# STM32N645xx register map
File version: 1.0
Registers are 32-bit, read-write, reset 0x0 unless marked. A register's access mark holds for its fields unless they carry their own. Offsets are from the block's base; [hi:lo] are bit positions; {n}, {i} and the like mark numbered series; 'fields as' and 'values as' point back to an identical list.

## ETH1 — Ethernet MAC
Base 0x48036000
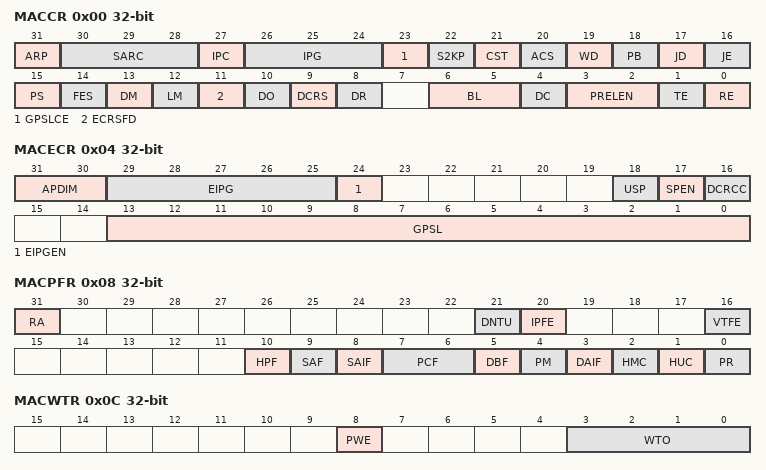
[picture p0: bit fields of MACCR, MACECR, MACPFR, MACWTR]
0x00 MACCR — Operating mode configuration register
  [31] ARP, [30:28] SARC, [27] IPC, [26:24] IPG, [23] GPSLCE, [22] S2KP, [21] CST, [20] ACS, [19] WD, [18] PB, [17] JD, [16] JE, [15] PS, [14] FES, [13] DM, [12] LM, [11] ECRSFD, [10] DO, [9] DCRS, [8] DR, [6:5] BL, [4] DC, [3:2] PRELEN, [1] TE, [0] RE
0x04 MACECR — Extended operating mode configuration register
  [31:30] APDIM, [29:25] EIPG, [24] EIPGEN, [18] USP, [17] SPEN, [16] DCRCC, [13:0] GPSL
0x08 MACPFR — Packet filtering control register
  [31] RA, [21] DNTU, [20] IPFE, [16] VTFE, [10] HPF, [9] SAF, [8] SAIF, [7:6] PCF, [5] DBF, [4] PM, [3] DAIF, [2] HMC, [1] HUC, [0] PR
0x0C MACWTR — Watchdog timeout register
  [8] PWE, [3:0] WTO
0x10 MACHT0R — Hash Table 0 register
0x14 MACHT1R — Hash Table 1 register
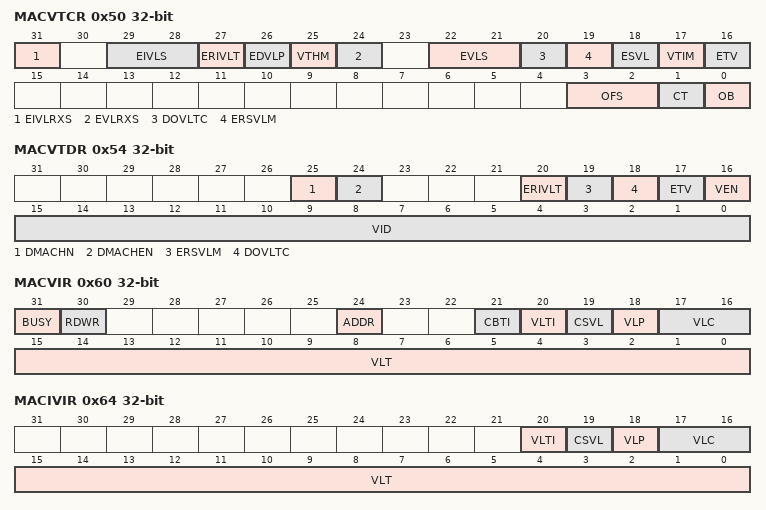
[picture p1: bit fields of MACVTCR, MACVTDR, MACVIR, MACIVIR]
0x50 MACVTCR — VLAN tag Control register
  [31] EIVLRXS, [29:28] EIVLS, [27] ERIVLT, [26] EDVLP, [25] VTHM, [24] EVLRXS, [22:21] EVLS, [20] DOVLTC, [19] ERSVLM, [18] ESVL, [17] VTIM, [16] ETV, [3:2] OFS, [1] CT, [0] OB
0x54 MACVTDR — VLAN tag data register
  [25] DMACHN, [24] DMACHEN, [20] ERIVLT, [19] ERSVLM, [18] DOVLTC, [17] ETV, [16] VEN, [15:0] VID
0x58 MACVHTR — VLAN Hash table register
  [15:0] VLHT
0x60 MACVIR — VLAN inclusion register
  [31] BUSY, [30] RDWR, [24] ADDR, [21] CBTI, [20] VLTI, [19] CSVL, [18] VLP, [17:16] VLC, [15:0] VLT
0x64 MACIVIR — Inner VLAN inclusion register
  [20] VLTI, [19] CSVL, [18] VLP, [17:16] VLC, [15:0] VLT
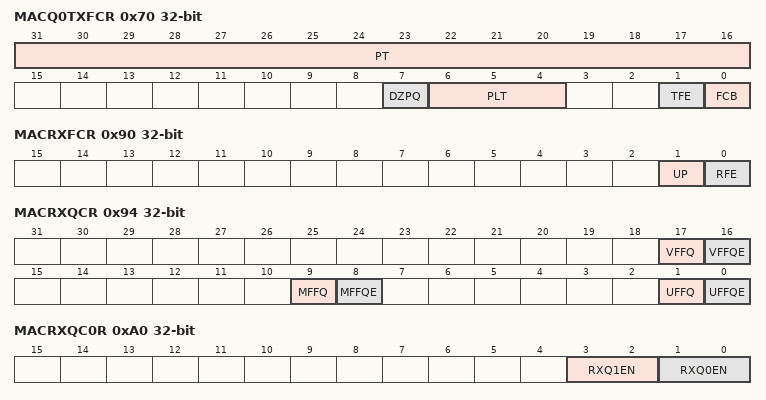
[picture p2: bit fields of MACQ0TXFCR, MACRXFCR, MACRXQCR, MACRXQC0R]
0x70 MACQ0TXFCR — Tx Queue 0 flow control register
  [31:16] PT, [7] DZPQ, [6:4] PLT, [1] TFE, [0] FCB
0x90 MACRXFCR — Rx flow control register
  [1] UP, [0] RFE
0x94 MACRXQCR — Rx Queue control register
  [17] VFFQ, [16] VFFQE, [9] MFFQ, [8] MFFQE, [1] UFFQ, [0] UFFQE
0xA0 MACRXQC0R — Rx queue control 0 register
  [3:2] RXQ1EN, [1:0] RXQ0EN
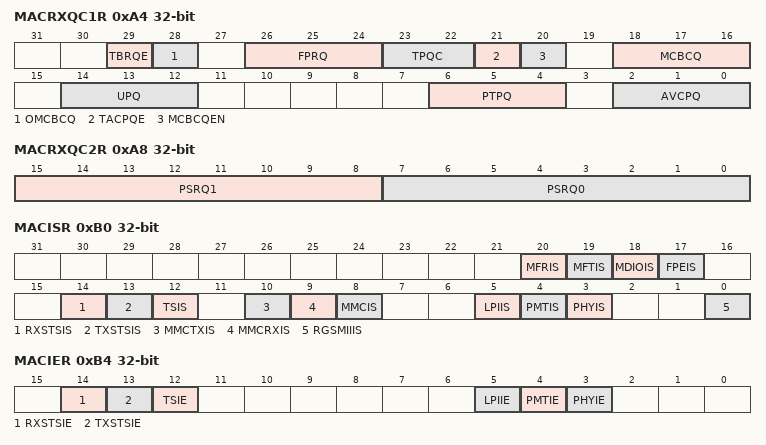
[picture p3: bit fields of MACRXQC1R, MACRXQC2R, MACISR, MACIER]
0xA4 MACRXQC1R — Rx queue control 1 register
  [29] TBRQE, [28] OMCBCQ, [26:24] FPRQ, [23:22] TPQC, [21] TACPQE, [20] MCBCQEN, [18:16] MCBCQ, [14:12] UPQ, [6:4] PTPQ, [2:0] AVCPQ
0xA8 MACRXQC2R — Rx queue control 2 register
  [15:8] PSRQ1, [7:0] PSRQ0
0xB0 MACISR — Interrupt status register
  [20] MFRIS, [19] MFTIS, [18] MDIOIS, [17] FPEIS, [14] RXSTSIS, [13] TXSTSIS, [12] TSIS, [10] MMCTXIS, [9] MMCRXIS, [8] MMCIS, [5] LPIIS, [4] PMTIS, [3] PHYIS, [0] RGSMIIIS
0xB4 MACIER — Interrupt enable register
  [14] RXSTSIE, [13] TXSTSIE, [12] TSIE, [5] LPIIE, [4] PMTIE, [3] PHYIE
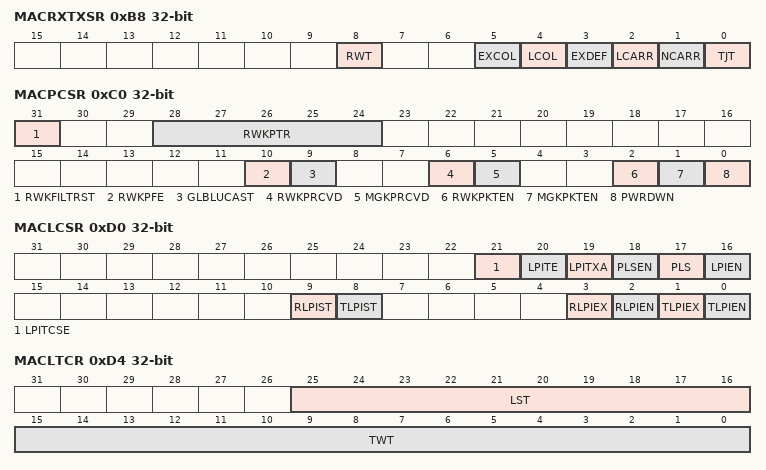
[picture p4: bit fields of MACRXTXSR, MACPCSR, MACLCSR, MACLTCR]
0xB8 MACRXTXSR — Rx Tx status register
  [8] RWT, [5] EXCOL, [4] LCOL, [3] EXDEF, [2] LCARR, [1] NCARR, [0] TJT
0xC0 MACPCSR — PMT control status register
  [31] RWKFILTRST, [28:24] RWKPTR, [10] RWKPFE, [9] GLBLUCAST, [6] RWKPRCVD, [5] MGKPRCVD, [2] RWKPKTEN, [1] MGKPKTEN, [0] PWRDWN
0xC4 MACRWKPFR — Remote wakeup packet filter register
0xD0 MACLCSR — LPI control and status register
  [21] LPITCSE, [20] LPITE, [19] LPITXA, [18] PLSEN, [17] PLS, [16] LPIEN, [9] RLPIST, [8] TLPIST, [3] RLPIEX, [2] RLPIEN, [1] TLPIEX, [0] TLPIEN
0xD4 MACLTCR — LPI timers control register
  [25:16] LST, [15:0] TWT
0xD8 MACLETR — LPI entry timer register
  [19:0] LPIET
0xDC MAC1USTCR — One-microsecond-tick counter register
  [11:0] TIC1USCNTR
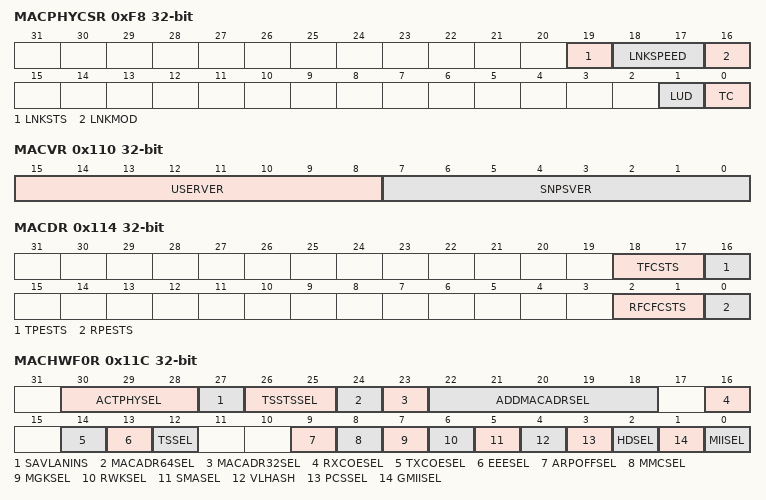
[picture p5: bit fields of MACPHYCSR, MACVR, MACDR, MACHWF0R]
0xF8 MACPHYCSR — PHYIF control status register
  [19] LNKSTS, [18:17] LNKSPEED, [16] LNKMOD, [1] LUD, [0] TC
0x110 MACVR — Version register
  [15:8] USERVER, [7:0] SNPSVER
0x114 MACDR — Debug register
  [18:17] TFCSTS, [16] TPESTS, [2:1] RFCFCSTS, [0] RPESTS
0x11C MACHWF0R — HW feature 0 register
  [30:28] ACTPHYSEL, [27] SAVLANINS, [26:25] TSSTSSEL, [24] MACADR64SEL, [23] MACADR32SEL, [22:18] ADDMACADRSEL, [16] RXCOESEL, [14] TXCOESEL, [13] EEESEL, [12] TSSEL, [9] ARPOFFSEL, [8] MMCSEL, [7] MGKSEL, [6] RWKSEL, [5] SMASEL, [4] VLHASH, [3] PCSSEL, [2] HDSEL, [1] GMIISEL, [0] MIISEL
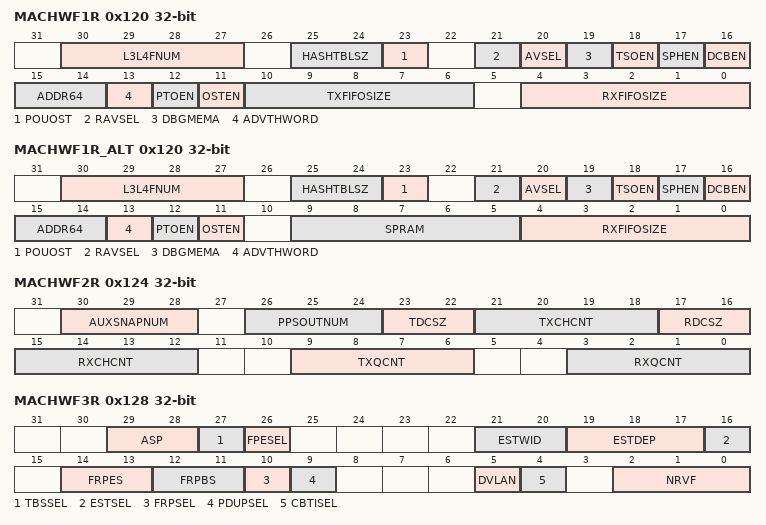
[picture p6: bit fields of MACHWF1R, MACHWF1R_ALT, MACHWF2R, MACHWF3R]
0x120 MACHWF1R — HW feature 1 register
  [30:27] L3L4FNUM, [25:24] HASHTBLSZ, [23] POUOST, [21] RAVSEL, [20] AVSEL, [19] DBGMEMA, [18] TSOEN, [17] SPHEN, [16] DCBEN, [15:14] ADDR64, [13] ADVTHWORD, [12] PTOEN, [11] OSTEN, [10:6] TXFIFOSIZE, [4:0] RXFIFOSIZE
0x120 MACHWF1R_ALT (alternate view of MACHWF1R) — HW feature 1 register
  [30:27] L3L4FNUM, [25:24] HASHTBLSZ, [23] POUOST, [21] RAVSEL, [20] AVSEL, [19] DBGMEMA, [18] TSOEN, [17] SPHEN, [16] DCBEN, [15:14] ADDR64, [13] ADVTHWORD, [12] PTOEN, [11] OSTEN, [9:5] SPRAM, [4:0] RXFIFOSIZE
0x124 MACHWF2R — HW feature 2 register
  [30:28] AUXSNAPNUM, [26:24] PPSOUTNUM, [23:22] TDCSZ, [21:18] TXCHCNT, [17:16] RDCSZ, [15:12] RXCHCNT, [9:6] TXQCNT, [3:0] RXQCNT
0x128 MACHWF3R — HW feature 3 register
  [29:28] ASP, [27] TBSSEL, [26] FPESEL, [21:20] ESTWID, [19:17] ESTDEP, [16] ESTSEL, [14:13] FRPES, [12:11] FRPBS, [10] FRPSEL, [9] PDUPSEL, [5] DVLAN, [4] CBTISEL, [2:0] NRVF
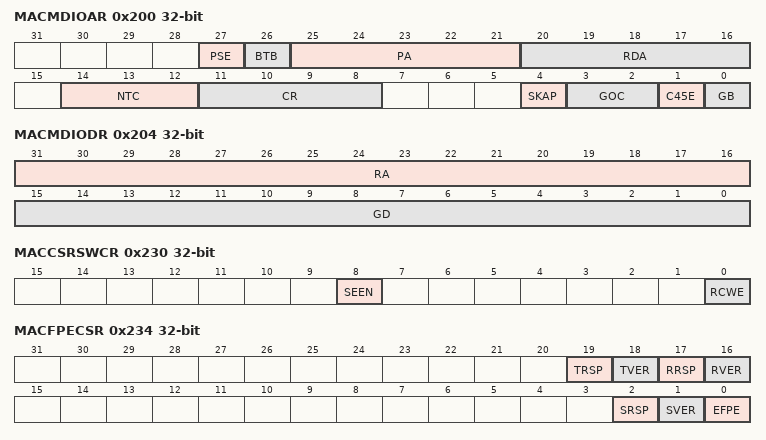
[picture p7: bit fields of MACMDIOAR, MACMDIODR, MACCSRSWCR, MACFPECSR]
0x200 MACMDIOAR — MDIO address register
  [27] PSE, [26] BTB, [25:21] PA, [20:16] RDA, [14:12] NTC, [11:8] CR, [4] SKAP, [3:2] GOC, [1] C45E, [0] GB
0x204 MACMDIODR — MDIO data register
  [31:16] RA, [15:0] GD
0x210 MACARPAR — ARP address register
  [31:0] ARPPA
0x230 MACCSRSWCR — CSR software control register
  [8] SEEN, [0] RCWE
0x234 MACFPECSR — FPE control and status register
  [19] TRSP, [18] TVER, [17] RRSP, [16] RVER, [2] SRSP, [1] SVER, [0] EFPE
0x240 MACPRSTIMR — MAC presentation time register
  [31:0] MPTN
0x244 MACPRSTIMUR — MAC presentation time update register
  [31:0] MPTU
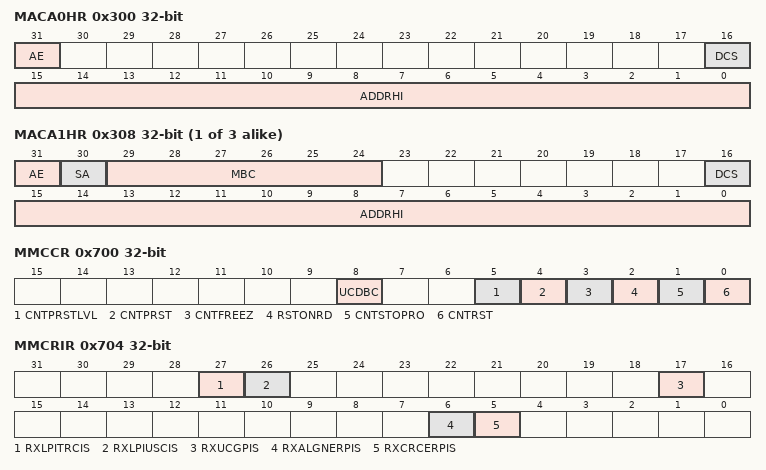
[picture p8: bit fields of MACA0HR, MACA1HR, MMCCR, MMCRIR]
0x300 MACA0HR — MAC Address 0 high register
  [31] AE, [16] DCS, [15:0] ADDRHI
{0x304+8i} MACA{i}LR (i=0..3) — MAC Address {i} low register
  [31:0] ADDRLO
{0x300+8i} MACA{i}HR (i=1..3) — MAC Address {i} high register
  [31] AE, [30] SA, [29:24] MBC, [16] DCS, [15:0] ADDRHI
0x700 MMCCR — MMC control register
  [8] UCDBC, [5] CNTPRSTLVL, [4] CNTPRST, [3] CNTFREEZ, [2] RSTONRD, [1] CNTSTOPRO, [0] CNTRST
0x704 MMCRIR — MMC Rx interrupt register
  [27] RXLPITRCIS, [26] RXLPIUSCIS, [17] RXUCGPIS, [6] RXALGNERPIS, [5] RXCRCERPIS
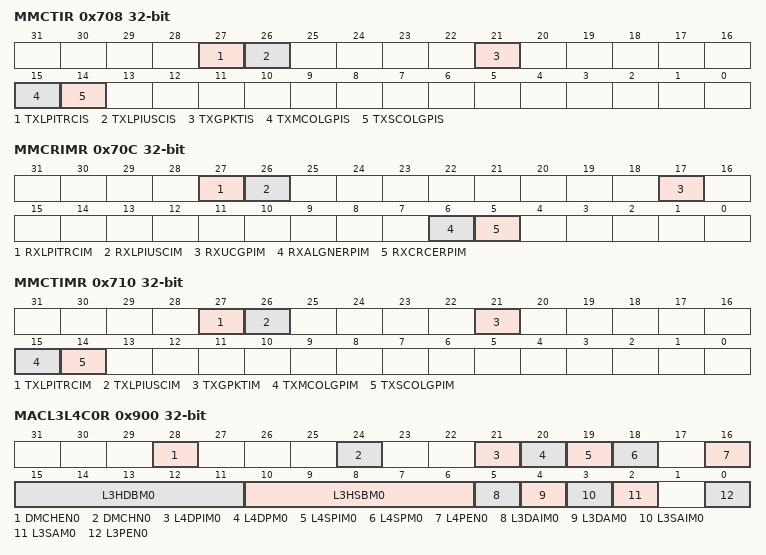
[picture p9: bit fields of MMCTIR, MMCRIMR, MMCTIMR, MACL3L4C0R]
0x708 MMCTIR — MMC Tx interrupt register
  [27] TXLPITRCIS, [26] TXLPIUSCIS, [21] TXGPKTIS, [15] TXMCOLGPIS, [14] TXSCOLGPIS
0x70C MMCRIMR — MMC Rx interrupt mask register
  [27] RXLPITRCIM, [26] RXLPIUSCIM, [17] RXUCGPIM, [6] RXALGNERPIM, [5] RXCRCERPIM
0x710 MMCTIMR — MMC Tx interrupt mask register
  [27] TXLPITRCIM, [26] TXLPIUSCIM, [21] TXGPKTIM, [15] TXMCOLGPIM, [14] TXSCOLGPIM
0x74C MMCTSCGPR — Tx single collision good packets register
0x750 MMCTMCGPR — Tx multiple collision good packets register
0x768 MMCTPCGR — Tx packet count good register
0x794 MMCRCRCEPR — Rx CRC error packets register
0x798 MMCRAEPR — Rx alignment error packets register
0x7C4 MMCRUPGR — Rx unicast packets good register
0x7EC MMCTLPIMSTR — Tx LPI microsecond timer register
0x7F0 MMCTLPITCR — Tx LPI transition counter register
0x7F4 MMCRLPIMSTR — Rx LPI microsecond counter register
0x7F8 MMCRLPITCR — Rx LPI transition counter register
0x8A0 MMCFPETISR — MMC FPE Tx interrupt status register
0x8A4 MMCFPETIMR — MMC FPE Tx interrupt mask register
0x8A8 MMCFPETFCR — MMC FPE Tx fragment counter register, -
0x8AC MMCTHRCR — MMC Tx hold request counter register
0x8C0 MMCFPERISR — MMC FPE Rx interrupt status register
0x8C4 MMCFPERIMR — MMC FPE Rx interrupt mask register
0x8C8 MMCRPAER — MMC Rx packet assembly error register
0x8CC MMCRPSMDER — MMC Rx packet SMD error register
0x8D0 MMCRPAOKR — MMC Rx packet assembly OK register
0x8D4 MMCFPERFCR — MMC Rx FPE fragments counter register
0x900 MACL3L4C0R — L3 and L4 control 0 register
  [28] DMCHEN0, [24] DMCHN0, [21] L4DPIM0, [20] L4DPM0, [19] L4SPIM0, [18] L4SPM0, [16] L4PEN0, [15:11] L3HDBM0, [10:6] L3HSBM0, [5] L3DAIM0, [4] L3DAM0, [3] L3SAIM0, [2] L3SAM0, [0] L3PEN0
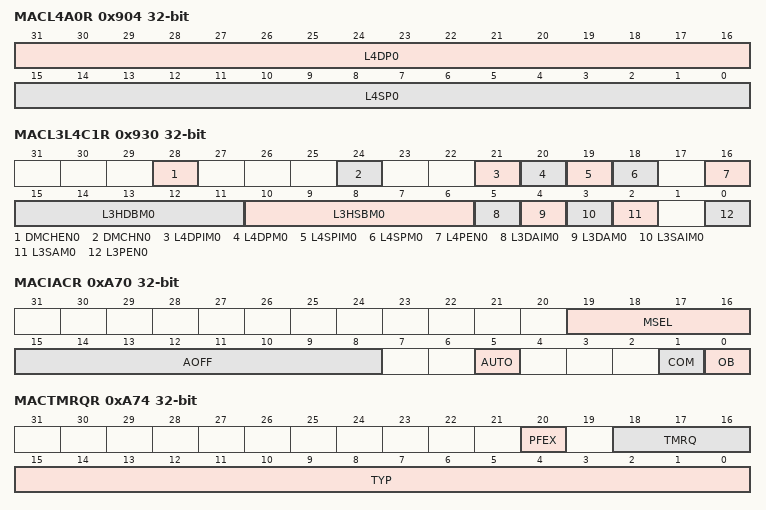
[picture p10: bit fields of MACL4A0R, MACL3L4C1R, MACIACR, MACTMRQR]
0x904 MACL4A0R — Layer4 Address filter 0 register
  [31:16] L4DP0, [15:0] L4SP0
{0x910+4i} MACL3A{i}R0R (i=0..3) — Layer3 Address {i} filter 0 register
  [31:0] L3A{i}
0x930 MACL3L4C1R — L3 and L4 control 1 register
  fields as MACL3L4C0R
0x934 MACL4A1R — Layer 4 address filter 1 register
0x940 MACL3A01R — Layer3 address 0 filter 1 Register
  [31:0] L3A0
0x944 MACL3A11R — Layer3 address 1 filter 1 register
  [31:0] L3A1
0x948 MACL3A21R — Layer3 address 2 filter 1 Register
  [31:0] L3A2
0x94C MACL3A31R — Layer3 address 3 filter 1 register
  [31:0] L3A3
0xA70 MACIACR — MAC Indirect Access Control register
  [19:16] MSEL, [15:8] AOFF, [5] AUTO, [1] COM, [0] OB
0xA74 MACTMRQR — MAC type-based Rx Queue mapping register
  [20] PFEX, [18:16] TMRQ, [15:0] TYP
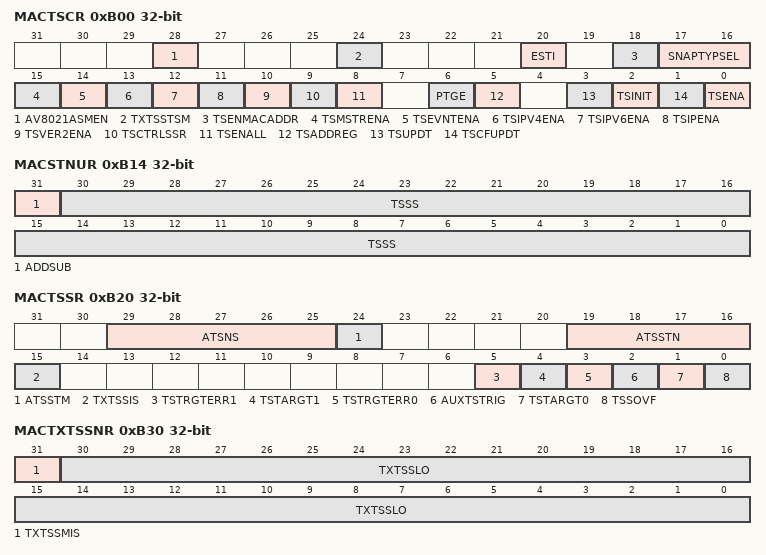
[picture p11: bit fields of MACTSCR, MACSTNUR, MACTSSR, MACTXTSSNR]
0xB00 MACTSCR — Timestamp control Register
  [28] AV8021ASMEN, [24] TXTSSTSM, [20] ESTI, [18] TSENMACADDR, [17:16] SNAPTYPSEL, [15] TSMSTRENA, [14] TSEVNTENA, [13] TSIPV4ENA, [12] TSIPV6ENA, [11] TSIPENA, [10] TSVER2ENA, [9] TSCTRLSSR, [8] TSENALL, [6] PTGE, [5] TSADDREG, [3] TSUPDT, [2] TSINIT, [1] TSCFUPDT, [0] TSENA
0xB04 MACSSIR — Subsecond increment register
  [31:0] TSS
0xB08 MACSTSR — System time seconds register
  [31:0] TSS
0xB0C MACSTNR — System time nanoseconds register
  [30:0] TSSS
0xB10 MACSTSUR — System time seconds update register
  [31:0] TSS
0xB14 MACSTNUR — System time nanoseconds update register
  [31] ADDSUB, [30:0] TSSS
0xB18 MACTSAR — Timestamp addend register
  [31:0] TSAR
0xB20 MACTSSR — Timestamp status register
  [29:25] ATSNS, [24] ATSSTM, [19:16] ATSSTN, [15] TXTSSIS, [5] TSTRGTERR1, [4] TSTARGT1, [3] TSTRGTERR0, [2] AUXTSTRIG, [1] TSTARGT0, [0] TSSOVF
0xB30 MACTXTSSNR — Tx timestamp status nanoseconds register
  [31] TXTSSMIS, [30:0] TXTSSLO
0xB34 MACTXTSSSR — Tx timestamp status seconds register
  [31:0] TXTSSHI
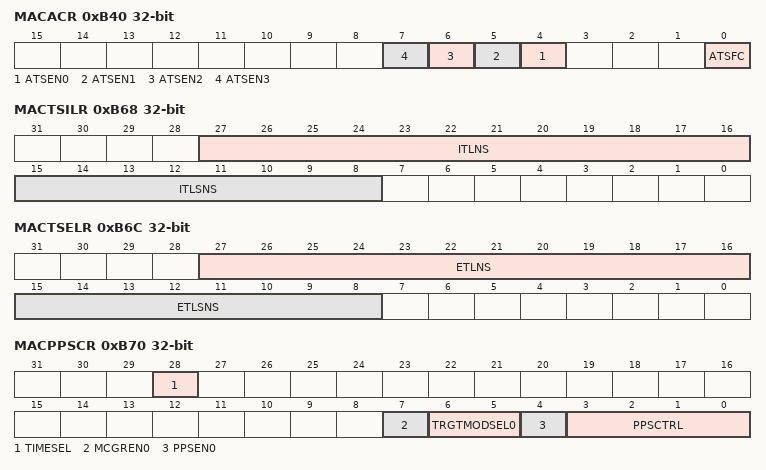
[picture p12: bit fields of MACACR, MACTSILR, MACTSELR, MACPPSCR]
0xB40 MACACR — Auxiliary control register
  [n+4] ATSEN{n} (n=0..3), [0] ATSFC
0xB48 MACATSNR — Auxiliary timestamp nanoseconds register
  [30:0] AUXTSLO
0xB4C MACATSSR — Auxiliary timestamp seconds register
  [31:0] AUXTSHI
0xB50 MACTSIACR — Timestamp Ingress asymmetric correction register
  [31:0] OSTIAC
0xB54 MACTSEACR — Timestamp Egress asymmetric correction register
  [31:0] OSTEAC
0xB58 MACTSICNR — Timestamp Ingress correction nanosecond register
  [31:0] TSIC
0xB5C MACTSECNR — Timestamp Egress correction nanosecond register
  [31:0] TSEC
0xB68 MACTSILR — Timestamp Ingress Latency register
  [27:16] ITLNS, [15:8] ITLSNS
0xB6C MACTSELR — Timestamp Egress Latency register
  [27:16] ETLNS, [15:8] ETLSNS
0xB70 MACPPSCR — PPS control register
  [28] TIMESEL, [7] MCGREN0, [6:5] TRGTMODSEL0, [4] PPSEN0, [3:0] PPSCTRL
0xB80 MACPPSTTS0R — PPS 0 target time seconds register
  [31:0] TSTRH0
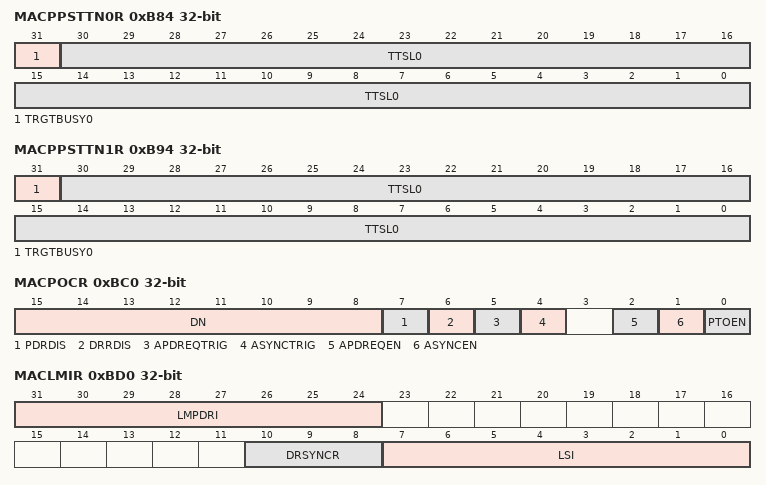
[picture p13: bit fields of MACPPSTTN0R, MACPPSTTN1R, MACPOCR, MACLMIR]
0xB84 MACPPSTTN0R — PPS 0 target time nanoseconds register
  [31] TRGTBUSY0, [30:0] TTSL0
0xB88 MACPPSI0R — PPS 0 interval register
  [31:0] PPSINT0
0xB8C MACPPSW0R — PPS 0 width register
  [31:0] PPSWIDTH0
0xB90 MACPPSTTS1R — PPS 1 target time seconds register
  [31:0] TSTRH0
0xB94 MACPPSTTN1R — PPS 1 target time nanoseconds register
  [31] TRGTBUSY0, [30:0] TTSL0
0xB98 MACPPSI1R — PPS 1 interval register
  [31:0] PPSINT0
0xB9C MACPPSW1R — PPS 1 width register
  [31:0] PPSWIDTH0
0xBC0 MACPOCR — PTP Offload control register
  [15:8] DN, [7] PDRDIS, [6] DRRDIS, [5] APDREQTRIG, [4] ASYNCTRIG, [2] APDREQEN, [1] ASYNCEN, [0] PTOEN
0xBC4 MACSPI0R — PTP Source Port Identity 0 Register
  [31:0] SPI0
0xBC8 MACSPI1R — PTP Source port identity 1 register
  [31:0] SPI1
0xBCC MACSPI2R — PTP Source port identity 2 register
  [15:0] SPI2
0xBD0 MACLMIR — Log message interval register
  [31:24] LMPDRI, [10:8] DRSYNCR, [7:0] LSI
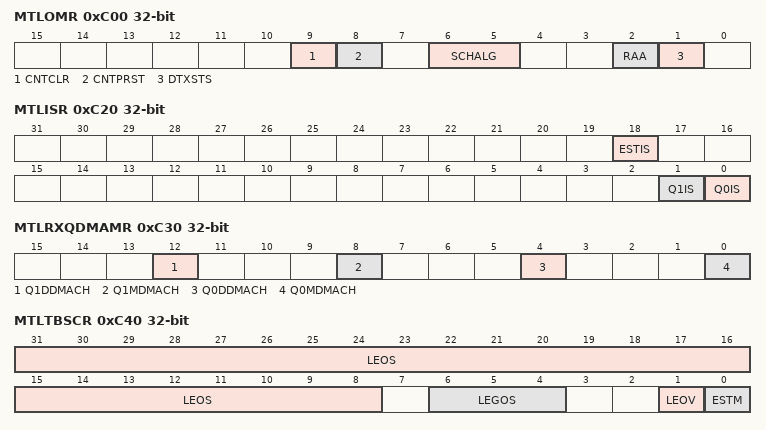
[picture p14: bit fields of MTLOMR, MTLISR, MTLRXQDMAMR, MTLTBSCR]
0xC00 MTLOMR — Operating mode Register
  [9] CNTCLR, [8] CNTPRST, [6:5] SCHALG, [2] RAA, [1] DTXSTS
0xC20 MTLISR — Interrupt status Register
  [18] ESTIS, [1] Q1IS, [0] Q0IS
0xC30 MTLRXQDMAMR — Rx Queue and DMA Channel Mapping Register
  [12] Q1DDMACH, [8] Q1MDMACH, [4] Q0DDMACH, [0] Q0MDMACH
0xC40 MTLTBSCR — TBS control register
  [31:8] LEOS, [6:4] LEGOS, [1] LEOV, [0] ESTM
0xC50 MTLESTCR — EST Control Register
  [31:24] PTOV, [23:12] CTOV, [10:8] TILS, [7:6] LCSE, [5] DFBS, [4] DDBF, [1] SSWL, [0] EEST
0xC54 MTLESTECR — EST Extended Control Register
  [5:0] OVHD
0xC58 MTLESTSR — EST Status Register
  [19:16] CGSN, [15:8] BTRL, [7] SWOL, [4] CGCE, [3] HLBS, [2] HLBF, [1] BTRE, [0] SWLC
0xC60 MTLESTSCHER — EST Schedule Error Register
  [1:0] SEQN
0xC64 MTLESTFSER — EST Frame size Error Register
  [1:0] FEQN
0xC68 MTLESTFSCR — EST Frame size Capture Register
  [16] HBFQ, [14:0] HBFS
0xC70 MTLESTIER — EST Interrupt Enable Register
  [4] CGCE, [3] IEHS, [2] IEHF, [1] IEBE, [0] IECC
0xC80 MTLESTGCLCR — EST Gate Control List Register
  [13:8] ADDR, [5] DBGB, [4] DBGM, [2] GCRR, [1] R1W0, [0] SRWO
0xC84 MTLESTGCLDR — EST Gate Control List Data Register
  [31:0] GCD
0xC90 MTLFPECSR — FPE Frame Preemption Control Status Register
  [28] HRS, [9:8] PEC, [1:0] AFSZ
0xC94 MTLFPEAR — FPE Frame Preemption Advance Register
  [31:16] RADV, [15:0] HADV
0xD00 MTLTXQ0OMR
  [19:16] TQS, [6:4] TTC, [3:2] TXQEN, [1] TSF, [0] FTQ
0xD04 MTLTXQ0UR
  [11] UFCNTOVF, [10:0] UFPKTCNT
0xD08 MTLTXQ0DR
  [22:20] STXSTSF, [18:16] PTXQ, [5] TXSTSFSTS, [4] TXQSTS, [3] TWCSTS, [2:1] TRCSTS, [0] TXQPAUSED
0xD10 MTLT1Q1ECR
  [6:4] SLC, [3] CC, [2] AVALG
0xD14 MTLTXQ0ESR
  [23:0] ABS
0xD18 MTLTXQ0QWR
  [6:0] ISCQW
0xD1C MTLT1Q1SSCR
  [13:0] SSC
0xD20 MTLT1Q1HCR
  [28:0] HC
0xD24 MTLT1Q1LCR
  [28:0] LC
0xD2C MTLQ0ICSR
  [24] RXOIE, [16] RXOVFIS, [9] ABPSIE, [8] TXUIE, [1] ABPSIS, [0] TXUNFIS
0xD30 MTLRXQ0OMR
  [23:20] RQS, [16:14] RFD, [7] EHFC, [6] DISTCPEF, [5] RSF, [4] FEP, [3] FUP, [1:0] RTC
0xD34 MTLRXQ0MPOCR
  [27] MISCNTOVF, [26:16] MISPKTCNT, [11] OVFCNTOVF, [10:0] OVFPKTCNT
0xD38 MTLRXQ0DR
  [29:16] PRXQ, [5:4] RXQSTS, [2:1] RRCSTS, [0] RWCSTS
0xD3C MTLRXQ0CR
  [3] RQPA, [2:0] RQW
0xD40 MTLTXQ1OMR
  [19:16] TQS, [6:4] TTC, [3:2] TXQEN, [1] TSF, [0] FTQ
0xD44 MTLTXQ1UR
  [11] UFCNTOVF, [10:0] UFPKTCNT
0xD48 MTLTXQ1DR
  fields as MTLTXQ0DR
0xD50 MTLT2Q1ECR
  [6:4] SLC, [3] CC, [2] AVALG
0xD54 MTLTXQ1ESR
  [23:0] ABS
0xD58 MTLTXQ1QWR
  [13:0] ISCQW
0xD5C MTLT2Q1SSCR
  [13:0] SSC
0xD60 MTLT2Q1HCR
  [28:0] HC
0xD64 MTLT2Q1LCR
  [28:0] LC
0xD6C MTLQ1ICSR
  fields as MTLQ0ICSR
0xD70 MTLRXQ1OMR
  fields as MTLRXQ0OMR
0xD74 MTLRXQ1MPOCR
  [27] MISCNTOVF, [26:16] MISPKTCNT, [11] OVFCNTOVF, [10:0] OVFPKTCNT
0xD78 MTLRXQ1DR
  [29:16] PRXQ, [5:4] RXQSTS, [2:1] RRCSTS, [0] RWCSTS
0xD7C MTLRXQ1CR
  [3] RQPA, [2:0] RQW
0x1000 DMAMR — DMA mode register
  [17:16] INTM, [11] TXPR, [8] DSPW, [4:2] TAA, [0] SWR
0x1004 DMASBMR — System bus mode register
  [31] ENLPI
  [30] LPIXPKT
  [25:24] WR_OSR_LMT — AXI Maximum Write Outstanding Request Limit
  [17:16] RD_OSR_LMT — AXI Maximum Read Outstanding Request Limit
  [13] ONEKBBE
  [12] AAL
  [10] AALE
  [7] BLEN256
  [6] BLEN128
  [5] BLEN64
  [4] BLEN32
  [3] BLEN16
  [2] BLEN8
  [1] BLEN4
  [0] FB
0x1008 DMAISR — Interrupt status register
  [17] MACIS, [16] MTLIS, [1] DMAC1IS, [0] DMAC0IS
0x100C DMADSR — Debug status register
  [23:20] TPS1, [19:16] RPS1, [15:12] TPS0, [11:8] RPS0, [1] AXRHSTS
0x1020 DMAA4TXACR — AXI4 transmit channel ACE control register
  [19:16] THC, [11:8] TEC, [3:0] TDRC
0x1024 DMAA4RXACR — AXI4 receive channel ACE control register
  [27:24] RDC, [19:16] RHC, [11:8] RPC, [3:0] RDWC
0x1028 DMAA4DACR — AXI4 descriptor ACE control register
  [11:8] RDRC, [7:4] TDWD, [3:0] TDWC
0x1040 DMALPIEI — AXI4 LPI Entry Interval register
  [3:0] LPIEI
0x1050 DMATBSCTRL0R — DMA TBS control register 0
  [31:8] FTOS, [6:4] FGOS, [0] FTOV
0x1100 DMAC0CR
  [20:18] DSL, [16] PBLX8, [13:0] MSS
0x1104 DMAC0TXCR
  [28] EDSE, [27:24] TQOS, [21:16] TXPBL, [15] IPBL, [12] TSE, [4] OSF, [3:1] TCW, [0] ST
0x1108 DMAC0RXCR
  [31] RPF, [27:24] RQOS, [21:16] RXPBL, [13:1] RBSZ, [0] SR
0x1114 DMAC0TXDLAR
  [31:0] TDESLA
0x111C DMAC0RXDLAR
  [31:0] RDESLA
0x1120 DMAC0TXDTPR
  [31:0] TDT
0x1128 DMAC0RXDTPR
  [31:0] TDT
0x112C DMAC0TXRLR
  [9:0] TDRL
0x1130 DMAC0RXRLR
  [23:17] ARBS, [9:0] RDRL
0x1134 DMAC0IER
  [15] NIE, [14] AIE, [13] CDEE, [12] FBEE, [11] ERIE, [10] ETIE, [9] RWTE, [8] RSE, [7] RBUE, [6] RIE, [2] TBUE, [1] TXSE, [0] TIE
0x1138 DMAC0RXIWTR
  [17:16] RWTU, [7:0] RWT
0x113C DMAC0SFCSR
  [19:16] RSN, [15:4] SIV, [1] ASC, [0] ESC
0x1144 DMAC0CATXDR
  [31:0] CURTDESAPTR
0x114C DMAC0CARXDR
  [31:0] CURRDESAPTR
0x1154 DMAC0CATXBR
  [31:0] CURTBUFAPTR
0x115C DMAC0CARXBR
  [31:0] CURRBUFAPTR
0x1160 DMAC0SR
  [21:19] REB, [18:16] TEB, [15] NIS, [14] AIS, [13] CDE, [12] FBE, [11] ERI, [10] ETI, [9] RWT, [8] RPS, [7] RBU, [6] RI, [2] TBU, [1] TPS, [0] TI
0x1164 DMAC0MFCR
  [15] MFCO, [10:0] MFC
0x1180 DMAC1CR
  [20:18] DSL, [16] PBLX8, [13:0] MSS
0x1184 DMAC1TXCR
  fields as DMAC0TXCR
0x1188 DMAC1RXCR
  [31] RPF, [27:24] RQOS, [21:16] RXPBL, [13:1] RBSZ, [0] SR
0x1194 DMAC1TXDLAR
  [31:0] TDESLA
0x119C DMAC1RXDLAR
  [31:0] RDESLA
0x11A0 DMAC1TXDTPR
  [31:0] TDT
0x11A8 DMAC1RXDTPR
  [31:0] TDT
0x11AC DMAC1TXRLR
  [9:0] TDRL
0x11B0 DMAC1RXRLR
  [23:17] ARBS, [9:0] RDRL
0x11B4 DMAC1IER
  fields as DMAC0IER
0x11B8 DMAC1RXIWTR
  [17:16] RWTU, [7:0] RWT
0x11BC DMAC1SFCSR
  [19:16] RSN, [15:4] SIV, [1] ASC, [0] ESC
0x11C4 DMAC1CATXDR
  [31:0] CURTDESAPTR
0x11CC DMAC1CARXDR
  [31:0] CURRDESAPTR
0x11D4 DMAC1CATXBR
  [31:0] CURTBUFAPTR
0x11DC DMAC1CARXBR
  [31:0] CURRBUFAPTR
0x11E0 DMAC1SR
  fields as DMAC0SR
0x11E4 DMAC1MFCR
  [15] MFCO, [10:0] MFC
